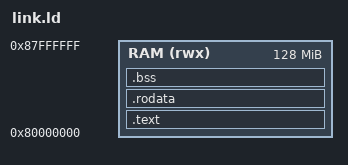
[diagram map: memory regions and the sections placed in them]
/* Карта памяти для машины virt. По сравнению с первой статьёй добавилась
   секция .bss: нам впервые понадобилась память, в которую можно писать.
   Строку из числа негде собирать, кроме как в ОЗУ. */

OUTPUT_ARCH(riscv)
ENTRY(_start)

MEMORY
{
    RAM (rwx) : ORIGIN = 0x80000000, LENGTH = 128M
}

SECTIONS
{
    .text : {
        *(.text)
        *(.text.*)
    } > RAM

    .rodata : {
        *(.rodata)
        *(.rodata.*)
    } > RAM

    /* Неинициализированные данные. Загружать нечего, поэтому линкеру
       достаточно знать адрес и размер. Обнулять при старте тоже некому,
       так что код обязан сам класть туда всё, что потом прочитает. */
    .bss : {
        *(.bss)
        *(.bss.*)
    } > RAM
}
